# ARMv7M register map
Registers are read-write, no defined reset value unless marked. A register's access mark holds for its fields unless they carry their own. Offsets are from the block's base; lines under a group give offsets from that group; [hi:lo] are bit positions; {n}, {i} and the like mark numbered series; 'fields as' and 'values as' point back to an identical list; <NAME> marks a mode.

## Memory map
0xE0000000 ITM size 0x1000 — Instrumentation Macrocell
0xE0001000 DWT size 0x1000 — Data Watchpoint and Trace
0xE0002000 FPB size 0x1000 — Flash Patch and Breakpoint
0xE000E004 ICB size 0xC — Implementation Control Block
0xE000E010 SYSTICK size 0x10 — SysTick Timer
0xE000ED90 MPU size 0x2C — Memory Protection Unit
0xE000EDF0 DCB size 0x10 — Debug Control Block
0xE000EF00 SIG size 0x4 — Software Interrupt Generation
0xE000EF34 FP size 0x18 — Floating-Point Extension
0xE0040000 TPIU size 0x1000 — Trace Port Interface Unit

## ITM — Instrumentation Macrocell
Base 0xE0000000
{0x0+4i} ITM_STIM[{i}] (i=0..255) — Stimulus Port Register provides the interface for generating instrumentation messages
  [31:0] STIMULUS — Data write to the stimulus port FIFO, for forwarding as a software event packet
  [0] FIFOREADY — Indicates whether the stimulus port FIFO can accept data
    0=Stimulus port FIFO full; 1=Stimulus port FIFO can accept at least one word
{0xE00+4i} ITM_TER[{i}] (i=0..7) — Trace Enable Register provides an individual enable bit for each STIM register
  [31:0] STIMENA — For bit STIMENA[n], in register ITM_TERx
    0=Stimulus port (32x + n) disabled; 1=Stimulus port (32x + n) enabled
0xE40 ITM_TPR — Trace Privilege Register controls which stimulus ports can be accessed by unprivileged code
  [31:0] PRIVMASK — Bit mask to enable unprivileged access to ITM stimulus ports
    0=Unprivileged access permitted; 1=Privileged access only
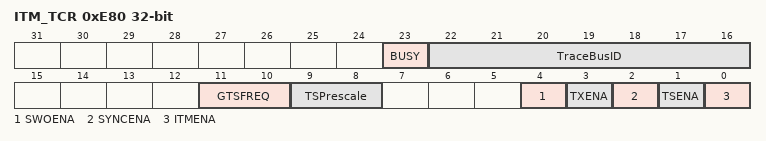
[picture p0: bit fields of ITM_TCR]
0xE80 ITM_TCR — Trace Control Register configures and controls transfers through the ITM interface
  [23] BUSY — Indicates whether the ITM is currently processing events
    0=ITM is not processing any events; 1=ITM events present and being drained
  [22:16] TraceBusID — Identifier for multi-source trace stream formatting
  [11:10] GTSFREQ — Global timestamp frequency
    0=Disable generation of global timestamps; 1=Generate timestamp request whenever the ITM detects a change in global timestamp counter bits[47:7]; 2=Generate timestamp request whenever the ITM detects a change in global timestamp counter bits[47:13]; 3=Generate a timestamp after every packet, if the output FIFO is empty
  [9:8] TSPrescale — Local timestamp prescaler, used with the trace packet reference clock
    0=No prescaling; 1=Divide by 4; 2=Divide by 16; 3=Divide by 64
  [4] SWOENA — Enables asynchronous clocking of the timestamp counter
    0=Timestamp counter uses the processor system clock; 1=Timestamp counter uses asynchronous clock from the TPIU interface
  [3] TXENA — Enables forwarding of hardware event packet from the DWT unit to the ITM for output to the TPIU
    0=Disabled; 1=Enabled
  [2] SYNCENA — Enables Synchronization packet transmission for a synchronous TPIU
    0=Disabled; 1=Enabled
  [1] TSENA — Enables Local timestamp generation
    0=Disabled; 1=Enabled
  [0] ITMENA — Enables the ITM

## FPB — Flash Patch and Breakpoint
Base 0xE0002000
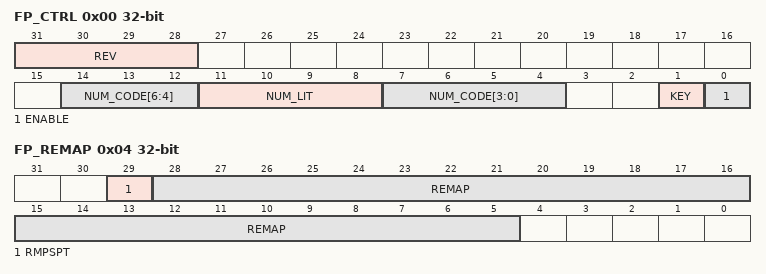
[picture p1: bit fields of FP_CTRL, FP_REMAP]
0x00 FP_CTRL — Flash Patch Control Register provides FPB implementation information, and the global enable for the FPB unit
  [31:28] REV — Flash Patch Breakpoint architecture revision
    0=Flash Patch Breakpoint version 1; 1=Flash Patch Breakpoint version 2
  [14:12] NUM_CODE[6:4] — Number of comperators 6:4
  [11:8] NUM_LIT — The number of literal address comparators supported, starting from NUM_CODE upwards
  [7:4] NUM_CODE[3:0] — Number of comperators 3:0
  [1] KEY — On any write to FP_CTRL, this bit must be 1
  [0] ENABLE — Enable bit for the FPB
    0=Flash Patch Breakpoint disabled; 1=Flash Patch Breakpoint enabled
0x04 FP_REMAP — Flash Patch Remap register indicates whether the implementation supports flash patch remap, and if it does, holds the SRAM address for remap
  [29] RMPSPT — Indicates whether the FPB unit supports flash patch remap
    0=Remapping not supported. The FPB only supports breakpoint functionality; 1=Hard-wired remap to SRAM region
  [28:5] REMAP — If the FPB supports flash patch remap, this field
{0x8+4i} FP_COMP[{i}] (i=0..7) — Flash Patch Comparator Register holds an address for comparison with addresses in the Code memory region
  [31] FE — Specifies if Flash Patch enabled
    0=Flash Patch disabled; 1=Flash Patch enabled
  [31:30] REPLACE — For an instruction address comparator: Defines the behavior when the COMP address is matched
    0=Remap to remap address; 1=Breakpoint on instruction at '000':COMP:'00'; 2=Breakpoint on instruction at '000':COMP:'10'; 3=Breakpoint on both instructions at '000':COMP:'00' and '000':COMP:'10'
  [28:2] COMP — Bits[28:2] of the address to compare with addresses from the Code memory region. Bits[31:29] of the address for comparison are zero. For a literal address or instruction address remap, bits[1:0] of the comparison are also zero. For an instruction address breakpoint, bits[1:0] of the comparison are encoded by the REPLACE field.
  [28:2] FPADDR — Specifies bits[28
  [31:1] BPADDR — Breakpoint address
  [31:1] DCBA — This field is defined depending on the value for Breakpoint Enabled
  [31:1] BPADDR — Breakpoint address
  [0] ENABLE — Enable bit for this comparator
    0=Comparator disabled; 1=Comparator enabled
  [0] BE — Enable bit for Breakpoint
    0=Breakpoint disabled; 1=Breakpoint enabled
  [0] BE — Breakpoint Enabled bit
    0=Breakpoint disabled; 1=Breakpoint enabled
